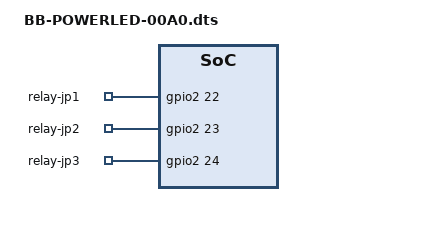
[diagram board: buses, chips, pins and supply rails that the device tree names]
/*
 * Copyright (C) 2015 Robert Nelson <robertcnelson@gmail.com>
 *
 * This program is free software; you can redistribute it and/or modify
 * it under the terms of the GNU General Public License version 2 as
 * published by the Free Software Foundation.
 */
/dts-v1/;
/plugin/;

#include <dt-bindings/board/am335x-bbw-bbb-base.h>
#include <dt-bindings/gpio/gpio.h>
#include <dt-bindings/pinctrl/am33xx.h>

/ {
	compatible = "ti,beaglebone", "ti,beaglebone-black", "ti,beaglebone-green";

	/* identification */
	part-number = "BB-POWERLED";
	version = "00A0";

	/* state the resources this cape uses */
	exclusive-use =
		/* the pin header uses */
		"P8.27",	/* gpio2_22 */
		"P8.29",	/* gpio2_23 */
		"P8.28",	/* gpio2_24 */
		/* the hardware ip uses */
		"gpio2_22",
		"gpio2_23",
		"gpio2_24";

	fragment@0 {
		target = <&am33xx_pinmux>;
		__overlay__ {

			bb_gpio_relay_pins: pinmux_bb_gpio_relay_pins {
				pinctrl-single,pins = <
					BONE_P9_27 (PIN_OUTPUT | MUX_MODE7)
					BONE_P9_29 (PIN_OUTPUT | MUX_MODE7)
					BONE_P9_28 (PIN_OUTPUT | MUX_MODE7)
				>;
			};

		};
	};

	fragment@1 {
		target-path="/";
		__overlay__ {

			leds {
				pinctrl-names = "default";
				pinctrl-0 = <&bb_gpio_relay_pins>;
				compatible = "gpio-leds";


				jp@1 {
					label = "relay-jp1";
					gpios = <&gpio2 22 GPIO_ACTIVE_HIGH>;
					default-state = "on";
				};

				jp@2 {
					label = "relay-jp2";
					gpios = <&gpio2 23 GPIO_ACTIVE_HIGH>;
					default-state = "off";
				};

				jp@3 {
					label = "relay-jp3";
					gpios = <&gpio2 24 GPIO_ACTIVE_HIGH>;
					default-state = "keep";
				};
			};
		};
	};
};
